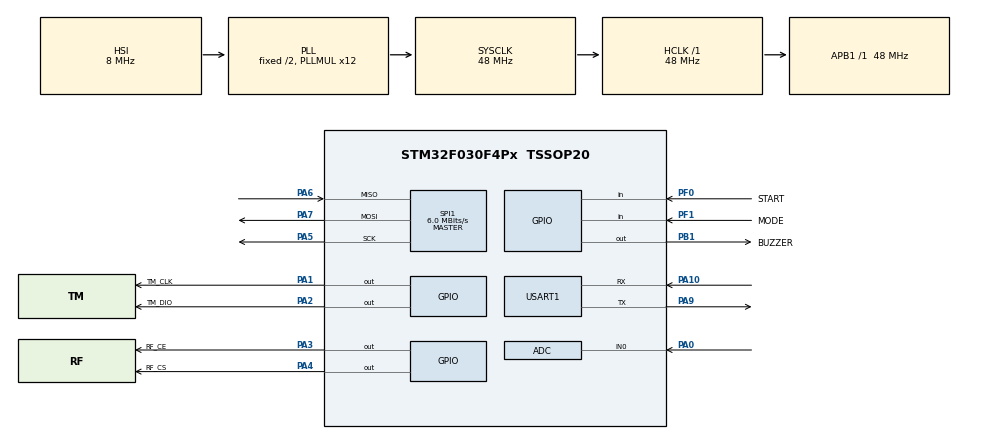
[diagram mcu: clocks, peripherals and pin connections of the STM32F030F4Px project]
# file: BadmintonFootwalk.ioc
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ADC.Resolution=ADC_RESOLUTION_12B
Dma.Request0=USART1_TX
Dma.Request1=USART1_RX
Dma.USART1_RX.1.Direction=DMA_PERIPH_TO_MEMORY
Dma.USART1_RX.1.Instance=DMA1_Channel3
Dma.USART1_RX.1.MemDataAlignment=DMA_MDATAALIGN_BYTE
Dma.USART1_RX.1.MemInc=DMA_MINC_ENABLE
Dma.USART1_RX.1.Mode=DMA_CIRCULAR
Dma.USART1_RX.1.PeriphDataAlignment=DMA_PDATAALIGN_BYTE
Dma.USART1_RX.1.PeriphInc=DMA_PINC_DISABLE
Dma.USART1_RX.1.Priority=DMA_PRIORITY_LOW
Dma.USART1_TX.0.Direction=DMA_MEMORY_TO_PERIPH
Dma.USART1_TX.0.Instance=DMA1_Channel2
Dma.USART1_TX.0.MemDataAlignment=DMA_MDATAALIGN_BYTE
Dma.USART1_TX.0.MemInc=DMA_MINC_ENABLE
Dma.USART1_TX.0.Mode=DMA_NORMAL
Dma.USART1_TX.0.PeriphDataAlignment=DMA_PDATAALIGN_BYTE
Dma.USART1_TX.0.PeriphInc=DMA_PINC_DISABLE
Dma.USART1_TX.0.Priority=DMA_PRIORITY_LOW
Mcu.Family=STM32F0
Mcu.Name=STM32F030F4Px
Mcu.Package=TSSOP20
NVIC.DMA1_Channel2_3_IRQn=true\:0\:0\:false\:false\:true\:false\:true\:true
NVIC.TIM14_IRQn=true\:0\:0\:false\:false\:true\:true\:true\:true
NVIC.TIM16_IRQn=true\:2\:0\:true\:false\:true\:true\:true\:true
NVIC.TIM1_BRK_UP_TRG_COM_IRQn=true\:3\:0\:false\:false\:true\:false\:true\:true
NVIC.TimeBase=TIM1_BRK_UP_TRG_COM_IRQn
NVIC.TimeBaseIP=TIM1
NVIC.USART1_IRQn=true\:0\:0\:false\:false\:true\:true\:true\:true
PA0.Mode=IN0
PA0.Signal=ADC_IN0
PA1.GPIO_Label=TM_CLK
PA1.GPIO_ModeDefaultOutputPP=GPIO_MODE_OUTPUT_OD
PA1.GPIO_PuPd=GPIO_PULLUP
PA1.Signal=GPIO_Output
PA10.Mode=Asynchronous
PA10.Signal=USART1_RX
PA2.GPIO_Label=TM_DIO
PA2.GPIO_ModeDefaultOutputPP=GPIO_MODE_OUTPUT_OD
PA2.GPIO_PuPd=GPIO_PULLUP
PA2.Signal=GPIO_Output
PA3.GPIO_Label=RF_CE
PA3.GPIO_ModeDefaultOutputPP=GPIO_MODE_OUTPUT_PP
PA3.GPIO_PuPd=GPIO_NOPULL
PA3.Signal=GPIO_Output
PA4.GPIO_Label=RF_CS
PA4.Signal=GPIO_Output
PA5.GPIO_PuPd=GPIO_PULLUP
PA5.Mode=Full_Duplex_Master
PA5.Signal=SPI1_SCK
PA6.Mode=Full_Duplex_Master
PA6.Signal=SPI1_MISO
PA7.Mode=Full_Duplex_Master
PA7.Signal=SPI1_MOSI
PA9.Mode=Asynchronous
PA9.Signal=USART1_TX
PB1.GPIO_Label=BUZZER
PB1.Signal=GPIO_Output
PF0-OSC_IN.GPIO_Label=START
PF0-OSC_IN.Signal=GPIO_Input
PF1-OSC_OUT.GPIO_Label=MODE
PF1-OSC_OUT.Signal=GPIO_Input
ProjectManager.HeapSize=0x200
ProjectManager.StackSize=0x400
ProjectManager.TargetToolchain=STM32CubeIDE
RCC.AHBFreq_Value=48000000
RCC.APB1Freq_Value=48000000
RCC.APB1TimFreq_Value=48000000
RCC.HCLKFreq_Value=48000000
RCC.PLLMUL=RCC_PLL_MUL12
RCC.SYSCLKFreq_VALUE=48000000
RCC.SYSCLKSource=RCC_SYSCLKSOURCE_PLLCLK
SPI1.BaudRatePrescaler=SPI_BAUDRATEPRESCALER_8
SPI1.CalculateBaudRate=6.0 MBits/s
SPI1.DataSize=SPI_DATASIZE_8BIT
SPI1.Direction=SPI_DIRECTION_2LINES
SPI1.Mode=SPI_MODE_MASTER
SPI1.VirtualType=VM_MASTER
TIM14.Period=49
TIM14.Prescaler=47
TIM16.Period=999
TIM16.Prescaler=47
TIM17.Prescaler=47
USART1.VirtualMode-Asynchronous=VM_ASYNC
VP_SYS_VS_tim1.Mode=TIM1
VP_TIM14_VS_ClockSourceINT.Mode=Enable_Timer
VP_TIM16_VS_ClockSourceINT.Mode=Enable_Timer
VP_TIM17_VS_ClockSourceINT.Mode=Enable_Timer
board=custom

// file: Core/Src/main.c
/* USER CODE BEGIN Header */
/**
  ******************************************************************************
  * @file           : main.c
  * @brief          : Main program body
  ******************************************************************************
  * @attention
  *
  * Copyright (c) 2026 STMicroelectronics.
  * All rights reserved.
  *
  * This software is licensed under terms that can be found in the LICENSE file
  * in the root directory of this software component.
  * If no LICENSE file comes with this software, it is provided AS-IS.
  *
  ******************************************************************************
  */
/* USER CODE END Header */
#include "main.h"
#include "adc.h"
#include "dma.h"
#include "spi.h"
#include "tim.h"
#include "usart.h"
#include "gpio.h"

/* USER CODE BEGIN Includes */
#include "bsp_log.h"
#include "uart_comm.h"
/* USER CODE END Includes */

void SystemClock_Config(void);

int main(void)
{

  /* MCU Configuration--------------------------------------------------------*/

  /* Reset of all peripherals, Initializes the Flash interface and the Systick. */
  HAL_Init();

  /* Configure the system clock */
  SystemClock_Config();

  /* Initialize all configured peripherals */
  MX_GPIO_Init();
  MX_DMA_Init();
  MX_SPI1_Init();
  MX_ADC_Init();
  MX_TIM17_Init();
  MX_TIM14_Init();
  MX_TIM16_Init();
  MX_USART1_UART_Init();

  /* Infinite loop */
  while (1)
  {

  }
}

void SystemClock_Config(void)
{
  RCC_OscInitTypeDef RCC_OscInitStruct = {0};
  RCC_ClkInitTypeDef RCC_ClkInitStruct = {0};
  RCC_PeriphCLKInitTypeDef PeriphClkInit = {0};

  /** Initializes the RCC Oscillators according to the specified parameters
  * in the RCC_OscInitTypeDef structure.
  */
  RCC_OscInitStruct.OscillatorType = RCC_OSCILLATORTYPE_HSI|RCC_OSCILLATORTYPE_HSI14;
  RCC_OscInitStruct.HSIState = RCC_HSI_ON;
  RCC_OscInitStruct.HSI14State = RCC_HSI14_ON;
  RCC_OscInitStruct.HSICalibrationValue = RCC_HSICALIBRATION_DEFAULT;
  RCC_OscInitStruct.HSI14CalibrationValue = 16;
  RCC_OscInitStruct.PLL.PLLState = RCC_PLL_ON;
  RCC_OscInitStruct.PLL.PLLSource = RCC_PLLSOURCE_HSI;
  RCC_OscInitStruct.PLL.PLLMUL = RCC_PLL_MUL12;
  RCC_OscInitStruct.PLL.PREDIV = RCC_PREDIV_DIV1;
  if (HAL_RCC_OscConfig(&RCC_OscInitStruct) != HAL_OK)
  {
    Error_Handler();
  }

  /** Initializes the CPU, AHB and APB buses clocks
  */
  RCC_ClkInitStruct.ClockType = RCC_CLOCKTYPE_HCLK|RCC_CLOCKTYPE_SYSCLK
                              |RCC_CLOCKTYPE_PCLK1;
  RCC_ClkInitStruct.SYSCLKSource = RCC_SYSCLKSOURCE_PLLCLK;
  RCC_ClkInitStruct.AHBCLKDivider = RCC_SYSCLK_DIV1;
  RCC_ClkInitStruct.APB1CLKDivider = RCC_HCLK_DIV1;

  if (HAL_RCC_ClockConfig(&RCC_ClkInitStruct, FLASH_LATENCY_1) != HAL_OK)
  {
    Error_Handler();
  }
  PeriphClkInit.PeriphClockSelection = RCC_PERIPHCLK_USART1;
  PeriphClkInit.Usart1ClockSelection = RCC_USART1CLKSOURCE_PCLK1;
  if (HAL_RCCEx_PeriphCLKConfig(&PeriphClkInit) != HAL_OK)
  {
    Error_Handler();
  }
}

void HAL_TIM_PeriodElapsedCallback(TIM_HandleTypeDef *htim)
{
  if (htim->Instance == TIM1)
  {
    HAL_IncTick();
  }
}

void Error_Handler(void)
{
  __disable_irq();
  while (1)
  {
  }
}
